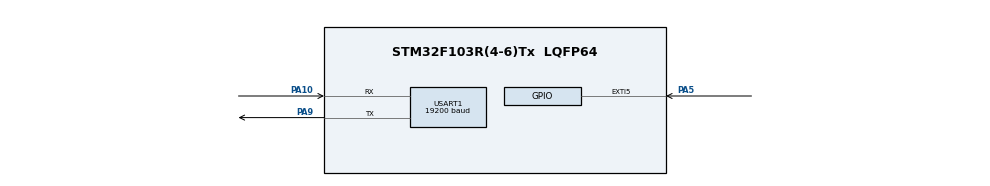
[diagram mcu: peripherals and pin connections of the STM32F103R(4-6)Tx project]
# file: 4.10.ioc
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Mcu.Family=STM32F1
Mcu.Name=STM32F103R(4-6)Tx
Mcu.Package=LQFP64
NVIC.EXTI9_5_IRQn=true\:0\:0\:false\:false\:true\:true\:true
NVIC.PriorityGroup=NVIC_PRIORITYGROUP_4
PA10.Mode=Asynchronous
PA10.Signal=USART1_RX
PA5.GPIO_PuPd=GPIO_PULLUP
PA5.Signal=GPXTI5
PA9.Mode=Asynchronous
PA9.Signal=USART1_TX
ProjectManager.HeapSize=0x200
ProjectManager.StackSize=0x400
ProjectManager.TargetToolchain=STM32CubeIDE
RCC.APB1Freq_Value=8000000
RCC.APB2Freq_Value=8000000
RTC.Date=20
RTC.Hours=12
RTC.Minutes=36
RTC.Month=RTC_MONTH_MAY
RTC.WeekDay=RTC_WEEKDAY_WEDNESDAY
RTC.Year=20
USART1.BaudRate=19200
USART1.Mode=MODE_TX_RX
USART1.VirtualMode=VM_ASYNC
VP_RTC_VS_RTC_Activate.Mode=RTC_Enabled
VP_RTC_VS_RTC_Calendar.Mode=RTC_Calendar
VP_SYS_VS_ND.Mode=No_Debug
board=custom

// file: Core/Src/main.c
/* USER CODE BEGIN Header */
/**
  ******************************************************************************
  * @file           : main.c
  * @brief          : Main program body
  ******************************************************************************
  * @attention
  *
  * <h2><center>&copy; Copyright (c) 2020 STMicroelectronics.
  * All rights reserved.</center></h2>
  *
  * This software component is licensed by ST under BSD 3-Clause license,
  * the "License"; You may not use this file except in compliance with the
  * License. You may obtain a copy of the License at:
  *                        opensource.org/licenses/BSD-3-Clause
  *
  ******************************************************************************
  */
/* USER CODE END Header */
#include "main.h"

/* USER CODE BEGIN Includes */
#include "stdio.h"
/* USER CODE END Includes */

RTC_HandleTypeDef hrtc;

UART_HandleTypeDef huart1;

void SystemClock_Config(void);
static void MX_GPIO_Init(void);
static void MX_RTC_Init(void);
static void MX_USART1_UART_Init(void);

int main(void)
{
  /* USER CODE BEGIN 1 */
	RTC_DateTypeDef sDateStructure;
	RTC_TimeTypeDef sTimeStructure;
	char sYear[5];
	char sMonth[3];
	char sDate[3];
	char sHour[3];
	char sMin[3];
	char sSec[3];
  /* USER CODE END 1 */

  /* MCU Configuration--------------------------------------------------------*/

  /* Reset of all peripherals, Initializes the Flash interface and the Systick. */
  HAL_Init();

  /* Configure the system clock */
  SystemClock_Config();

  /* Initialize all configured peripherals */
  MX_GPIO_Init();
  MX_RTC_Init();
  MX_USART1_UART_Init();

  /* Infinite loop */
  /* USER CODE BEGIN WHILE */
  while (1)
  {
	  HAL_RTC_GetTime(&hrtc, &sTimeStructure, RTC_FORMAT_BIN);  //十进�??
	  HAL_RTC_GetDate(&hrtc, &sDateStructure, RTC_FORMAT_BCD);  //BCD
	  sprintf(sYear,"%04x",0x2000+sDateStructure.Year);
	  sprintf(sMonth,"%02x",sDateStructure.Month);
	  sprintf(sDate,"%02x",sDateStructure.Date);
	  sprintf(sHour,"%02d",sTimeStructure.Hours);
	  sprintf(sMin,"%02d",sTimeStructure.Minutes);
	  sprintf(sSec,"%02d",sTimeStructure.Seconds);
	  /* 打印日期 */
	  HAL_UART_Transmit(&huart1,sYear,4,4);
	  HAL_UART_Transmit(&huart1,&"-",1,1);
	  HAL_UART_Transmit(&huart1,sMonth,2,2);
	  HAL_UART_Transmit(&huart1,&"-",1,1);
	  HAL_UART_Transmit(&huart1,sDate,2,2);
	  HAL_UART_Transmit(&huart1,&" ",1,2);
	  /* 打印时间 */
	  HAL_UART_Transmit(&huart1,sHour,2,2);
	  HAL_UART_Transmit(&huart1,&":",1,1);
	  HAL_UART_Transmit(&huart1,sMin,2,2);
	  HAL_UART_Transmit(&huart1,&":",1,1);
	  HAL_UART_Transmit(&huart1,sSec,2,2);
	  HAL_UART_Transmit(&huart1,&"\n\r",2,2);

	  HAL_Delay(1000);
    /* USER CODE END WHILE */

  }
}

void SystemClock_Config(void)
{
  RCC_OscInitTypeDef RCC_OscInitStruct = {0};
  RCC_ClkInitTypeDef RCC_ClkInitStruct = {0};
  RCC_PeriphCLKInitTypeDef PeriphClkInit = {0};

  /** Initializes the RCC Oscillators according to the specified parameters
  * in the RCC_OscInitTypeDef structure.
  */
  RCC_OscInitStruct.OscillatorType = RCC_OSCILLATORTYPE_HSI|RCC_OSCILLATORTYPE_LSI;
  RCC_OscInitStruct.HSIState = RCC_HSI_ON;
  RCC_OscInitStruct.HSICalibrationValue = RCC_HSICALIBRATION_DEFAULT;
  RCC_OscInitStruct.LSIState = RCC_LSI_ON;
  RCC_OscInitStruct.PLL.PLLState = RCC_PLL_NONE;
  if (HAL_RCC_OscConfig(&RCC_OscInitStruct) != HAL_OK)
  {
    Error_Handler();
  }
  /** Initializes the CPU, AHB and APB buses clocks
  */
  RCC_ClkInitStruct.ClockType = RCC_CLOCKTYPE_HCLK|RCC_CLOCKTYPE_SYSCLK
                              |RCC_CLOCKTYPE_PCLK1|RCC_CLOCKTYPE_PCLK2;
  RCC_ClkInitStruct.SYSCLKSource = RCC_SYSCLKSOURCE_HSI;
  RCC_ClkInitStruct.AHBCLKDivider = RCC_SYSCLK_DIV1;
  RCC_ClkInitStruct.APB1CLKDivider = RCC_HCLK_DIV1;
  RCC_ClkInitStruct.APB2CLKDivider = RCC_HCLK_DIV1;

  if (HAL_RCC_ClockConfig(&RCC_ClkInitStruct, FLASH_LATENCY_0) != HAL_OK)
  {
    Error_Handler();
  }
  PeriphClkInit.PeriphClockSelection = RCC_PERIPHCLK_RTC;
  PeriphClkInit.RTCClockSelection = RCC_RTCCLKSOURCE_LSI;
  if (HAL_RCCEx_PeriphCLKConfig(&PeriphClkInit) != HAL_OK)
  {
    Error_Handler();
  }
}

static void MX_RTC_Init(void)
{

  RTC_TimeTypeDef sTime = {0};
  RTC_DateTypeDef DateToUpdate = {0};

  /** Initialize RTC Only
  */
  hrtc.Instance = RTC;
  hrtc.Init.AsynchPrediv = RTC_AUTO_1_SECOND;
  hrtc.Init.OutPut = RTC_OUTPUTSOURCE_ALARM;
  if (HAL_RTC_Init(&hrtc) != HAL_OK)
  {
    Error_Handler();
  }

  /** Initialize RTC and set the Time and Date
  */
  sTime.Hours = 0x12;
  sTime.Minutes = 0x36;
  sTime.Seconds = 0x0;

  if (HAL_RTC_SetTime(&hrtc, &sTime, RTC_FORMAT_BCD) != HAL_OK)
  {
    Error_Handler();
  }
  DateToUpdate.WeekDay = RTC_WEEKDAY_WEDNESDAY;
  DateToUpdate.Month = RTC_MONTH_MAY;
  DateToUpdate.Date = 0x20;
  DateToUpdate.Year = 0x20;

  if (HAL_RTC_SetDate(&hrtc, &DateToUpdate, RTC_FORMAT_BCD) != HAL_OK)
  {
    Error_Handler();
  }

}

static void MX_USART1_UART_Init(void)
{

  huart1.Instance = USART1;
  huart1.Init.BaudRate = 19200;
  huart1.Init.WordLength = UART_WORDLENGTH_8B;
  huart1.Init.StopBits = UART_STOPBITS_1;
  huart1.Init.Parity = UART_PARITY_NONE;
  huart1.Init.Mode = UART_MODE_TX_RX;
  huart1.Init.HwFlowCtl = UART_HWCONTROL_NONE;
  huart1.Init.OverSampling = UART_OVERSAMPLING_16;
  if (HAL_UART_Init(&huart1) != HAL_OK)
  {
    Error_Handler();
  }

}

static void MX_GPIO_Init(void)
{
  GPIO_InitTypeDef GPIO_InitStruct = {0};

  /* GPIO Ports Clock Enable */
  __HAL_RCC_GPIOA_CLK_ENABLE();

  /*Configure GPIO pin : PA5 */
  GPIO_InitStruct.Pin = GPIO_PIN_5;
  GPIO_InitStruct.Mode = GPIO_MODE_IT_RISING;
  GPIO_InitStruct.Pull = GPIO_PULLUP;
  HAL_GPIO_Init(GPIOA, &GPIO_InitStruct);

  /* EXTI interrupt init*/
  HAL_NVIC_SetPriority(EXTI9_5_IRQn, 0, 0);
  HAL_NVIC_EnableIRQ(EXTI9_5_IRQn);

}

/* USER CODE BEGIN 4 */
void HAL_GPIO_EXTI_Callback(uint16_t GPIO_Pin)
{
	RTC_DateTypeDef sDateStructure;
	RTC_TimeTypeDef sTimeStructure;
	if(GPIO_Pin==GPIO_PIN_5)  //检测到EXTI5线产生外部中断事件
	{
		sDateStructure.Year=20;
		sDateStructure.Month=5;
		sDateStructure.Date=20;
		sDateStructure.WeekDay=3;
		HAL_RTC_SetDate(&hrtc,&sDateStructure,RTC_FORMAT_BIN);  //十进�?
		sTimeStructure.Hours=0x12;
		sTimeStructure.Minutes=0x36;
		sTimeStructure.Seconds=0;
		HAL_RTC_SetTime(&hrtc, &sTimeStructure, RTC_FORMAT_BCD);  //BCD
		while(HAL_GPIO_ReadPin(GPIOA,GPIO_PIN_5)==GPIO_PIN_RESET);
	}
}
/* USER CODE END 4 */

void Error_Handler(void)
{
}

/************************ (C) COPYRIGHT STMicroelectronics *****END OF FILE****/
